# RockChip_RK3588 register map
Vendor: RockChip Electronics Co., Ltd.; Series: RK3588; File version: 0.1
Registers are 32-bit, read-write, no defined reset value unless marked. A register's access mark holds for its fields unless they carry their own. Offsets are from the block's base; [hi:lo] are bit positions; {n}, {i} and the like mark numbered series.

## GRF_PMU1
Base 0xFD58A000
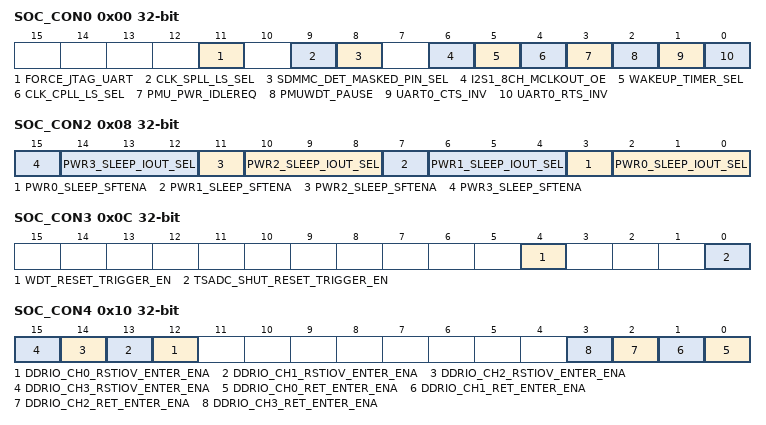
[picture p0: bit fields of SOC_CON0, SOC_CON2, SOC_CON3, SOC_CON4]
0x00 SOC_CON0 — System control register 0
  [11] FORCE_JTAG_UART — Enable GPIO0b5 and GPIO0b6 switch to JTAG function if uart2_rx low last for a specified period of time.
    0=DISABLE; 1=ENABLE
  [9] CLK_SPLL_LS_SEL — Path selection for SPLL clock output.
    0=NORMAL; 1=THROUGH_LEVEL_SHIFT_CELL
  [8] SDMMC_DET_MASKED_PIN_SEL — Polarity selection for sdmmc_det_masked_pin.
    0=LOW_ACTIVE; 1=HIGH_ACTIVE
  [6] I2S1_8CH_MCLKOUT_OE — Output enable for i2s1_8ch_mclkout.
    0=DISABLE; 1=ENABLE
  [5] WAKEUP_TIMER_SEL — Select PMU_TIMER interrupt as PMU wake up source.
    0=INT_0 (PMU_TIMER interrupt 0 selected); 1=INT_1 (PMU_TIMER interrupt 1 selected)
  [4] CLK_CPLL_LS_SEL — Path selection for CPLL clock output.
    0=NORMAL; 1=THROUGH_LEVEL_SHIFT_CELL
  [3] PMU_PWR_IDLEREQ — Enable PD_PMU1 idle request by software.
    0=DISABLE; 1=ENABLE
  [2] PMUWDT_PAUSE — PMU_WDT wdt pause enable. It is used to freeze the watchdog counter during pause mode
    0=DISABLE; 1=ENABLE
  [1] UART0_CTS_INV — Polarity selection for uart0_cts.
    0=LOW_ACTIVE; 1=HIGH_ACTIVE
  [0] UART0_RTS_INV — Polarity selection for uart0_rts.
    0=LOW_ACTIVE; 1=HIGH_ACTIVE
0x04 SOC_CON1 — System control register 1
  [15:0] RESET_WIDTH — The chip output reset width, equals to reset_width*256.
0x08 SOC_CON2 — System control register 2
  [4n+3] PWR{n}_SLEEP_SFTENA (n=0..3) — Enable pwr{n}_sleep by software.
    0=DISABLE; 1=ENABLE
  [4n+2:4n] PWR{n}_SLEEP_IOUT_SEL (n=0..3) — Source selection for pwr{n}_sleep. Default: Controlled by pwr{n}_sleep_sftena
    1=VD_NPU (VD_NPU power off request); 2=VD_GPU (VD_GPU power off request); 3=VD_BIGCORE0 (VD_BIGCORE0 power off request); 4=VD_BIGCORE1 (VD_BIGCORE1 power off request); 5=VD_DSU (VD_DSU power off request); 6=VD_VCODEC (VD_VCODEC power off request); 7=VD_DDR (VD_DDR power off request)
0x0C SOC_CON3 — System control register 3
  [4] WDT_RESET_TRIGGER_EN — Enable WDT reset trigger for DDR fail safe.
    0=DISABLE; 1=ENABLE
  [0] TSADC_SHUT_RESET_TRIGGER_EN — Enable TSADC shut reset trigger for DDR fail safe.
    0=DISABLE; 1=ENABLE
0x10 SOC_CON4 — System control register 4
  [all] fields
    0=DISABLE; 1=ENABLE
  [n+12] DDRIO_CH{n}_RSTIOV_ENTER_ENA (n=0..3) — Enable DDR IO enter retention mode through RSTIOV by hardware for DDR fail safe.
  [n] DDRIO_CH{n}_RET_ENTER_ENA (n=0..3) — Enable DDR IO enter retention mode through RETON/RETOFF or RSTIOV by hardware for DDR fail safe.
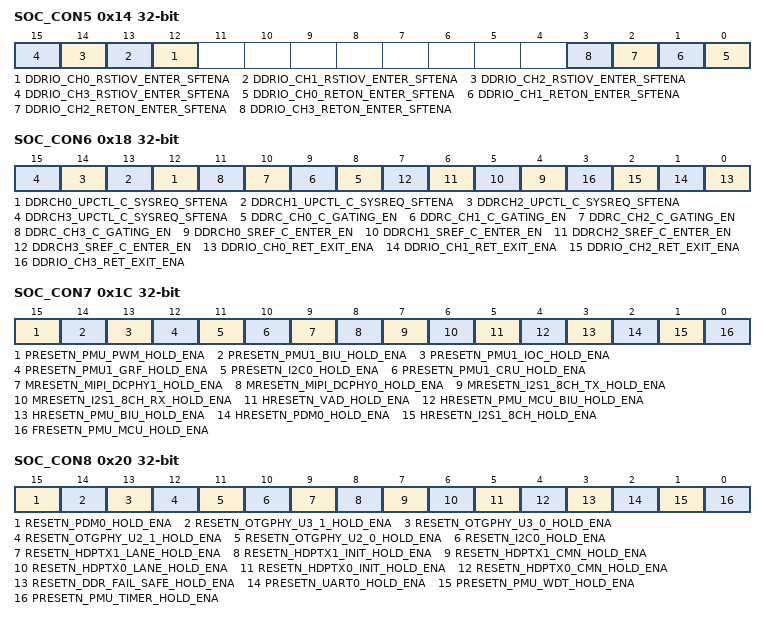
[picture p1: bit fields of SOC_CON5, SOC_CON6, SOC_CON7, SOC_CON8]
0x14 SOC_CON5 — System control register 5
  [all] fields
    0=DISABLE; 1=ENABLE
  [n+12] DDRIO_CH{n}_RSTIOV_ENTER_SFTENA (n=0..3) — Enable DDR IO enter retention mode through RSTIOV by software for DDR fail safe.
  [n] DDRIO_CH{n}_RETON_ENTER_SFTENA (n=0..3) — Enable DDR IO enter retention mode through RETON/RETOFF by software for DDR fail safe.
0x18 SOC_CON6 — System control register 6
  [all] fields
    0=DISABLE; 1=ENABLE
  [n+12] DDRCH{n}_UPCTL_C_SYSREQ_SFTENA (n=0..3) — Enable for DDRC hardware low-power clock request by software.
  [n+8] DDRC_CH{n}_C_GATING_EN (n=0..3) — Enable DDRCTRL's core-clock auto clock gating for DDR fail safe.
  [n+4] DDRCH{n}_SREF_C_ENTER_EN (n=0..3) — Enable DDR self-refresh mode for core-clock domain by hardware for DDR fail safe.
  [n] DDRIO_CH{n}_RET_EXIT_ENA (n=0..3) — Enable DDR IO exit retention mode through RETON/RETOFF or RSTIOV by hardware for DDR fail safe.
0x1C SOC_CON7 — System control register 7
  [all] fields
    0=DISABLE; 1=ENABLE
  [15] PRESETN_PMU_PWM_HOLD_ENA — Enable reset hold for presetn_pmu_pwm.
  [14] PRESETN_PMU1_BIU_HOLD_ENA — Enable reset hold for presetn_pmu1_biu.
  [13] PRESETN_PMU1_IOC_HOLD_ENA — Enable reset hold for presetn_pmu1_ioc.
  [12] PRESETN_PMU1_GRF_HOLD_ENA — Enable reset hold for presetn_pmu1_grf.
  [11] PRESETN_I2C0_HOLD_ENA — Enable reset hold for presetn_i2c0.
  [10] PRESETN_PMU1_CRU_HOLD_ENA — Enable reset hold for presetn_pmu1_cru.
  [9] MRESETN_MIPI_DCPHY1_HOLD_ENA — Enable reset hold for mresetn_mipi_dcphy1.
  [8] MRESETN_MIPI_DCPHY0_HOLD_ENA — Enable reset hold for mresetn_mipi_dcphy0.
  [7] MRESETN_I2S1_8CH_TX_HOLD_ENA — Enable reset hold for mresetn_i2s1_8ch_tx.
  [6] MRESETN_I2S1_8CH_RX_HOLD_ENA — Enable reset hold for mresetn_i2s1_8ch_rx.
  [5] HRESETN_VAD_HOLD_ENA — Enable reset hold for hresetn_vad.
  [4] HRESETN_PMU_MCU_BIU_HOLD_ENA — Enable reset hold for hresetn_pmu_mcu_biu.
  [3] HRESETN_PMU_BIU_HOLD_ENA — Enable reset hold for hresetn_pmu_biu.
  [2] HRESETN_PDM0_HOLD_ENA — Enable reset hold for hresetn_pdm0.
  [1] HRESETN_I2S1_8CH_HOLD_ENA — Enable reset hold for hresetn_i2s1_8ch.
  [0] FRESETN_PMU_MCU_HOLD_ENA — Enable reset hold for fresetn_pmu_mcu.
0x20 SOC_CON8 — System control register 8
  [all] fields
    0=DISABLE; 1=ENABLE
  [15] RESETN_PDM0_HOLD_ENA — Enable reset hold for resetn_pdm0.
  [14] RESETN_OTGPHY_U3_1_HOLD_ENA — Enable reset hold for resetn_otgphy_u3_1.
  [13] RESETN_OTGPHY_U3_0_HOLD_ENA — Enable reset hold for resetn_otgphy_u3_0.
  [12] RESETN_OTGPHY_U2_1_HOLD_ENA — Enable reset hold for resetn_otgphy_u2_1.
  [11] RESETN_OTGPHY_U2_0_HOLD_ENA — Enable reset hold for resetn_otgphy_u2_0.
  [10] RESETN_I2C0_HOLD_ENA — Enable reset hold for resetn_i2c0.
  [9] RESETN_HDPTX1_LANE_HOLD_ENA — Enable reset hold for resetn_hdptx1_lane.
  [8] RESETN_HDPTX1_INIT_HOLD_ENA — Enable reset hold for resetn_hdptx1_init.
  [7] RESETN_HDPTX1_CMN_HOLD_ENA — Enable reset hold for resetn_hdptx1_cmn.
  [6] RESETN_HDPTX0_LANE_HOLD_ENA — Enable reset hold for resetn_hdptx0_lane.
  [5] RESETN_HDPTX0_INIT_HOLD_ENA — Enable reset hold for resetn_hdptx0_init.
  [4] RESETN_HDPTX0_CMN_HOLD_ENA — Enable reset hold for resetn_hdptx0_cmn.
  [3] RESETN_DDR_FAIL_SAFE_HOLD_ENA — Enable reset hold for resetn_ddr_fail_safe.
  [2] PRESETN_UART0_HOLD_ENA — Enable reset hold for presetn_uart0.
  [1] PRESETN_PMU_WDT_HOLD_ENA — Enable reset hold for presetn_pmu_wdt.
  [0] PRESETN_PMU_TIMER_HOLD_ENA — Enable reset hold for presetn_pmu_timer.
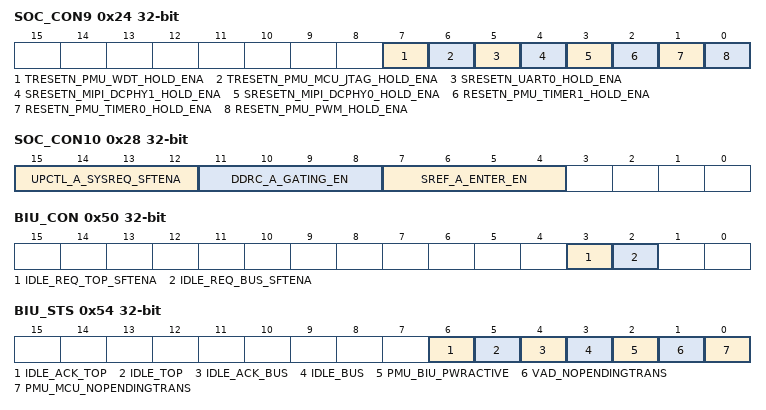
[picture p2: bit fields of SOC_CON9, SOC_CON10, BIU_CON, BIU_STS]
0x24 SOC_CON9 — System control register 9
  [all] fields
    0=DISABLE; 1=ENABLE
  [7] TRESETN_PMU_WDT_HOLD_ENA — Enable reset hold for tresetn_pmu_wdt.
  [6] TRESETN_PMU_MCU_JTAG_HOLD_ENA — Enable reset hold for tresetn_pmu_mcu_jtag.
  [5] SRESETN_UART0_HOLD_ENA — Enable reset hold for sresetn_uart0.
  [4] SRESETN_MIPI_DCPHY1_HOLD_ENA — Enable reset hold for sresetn_mipi_dcphy1.
  [3] SRESETN_MIPI_DCPHY0_HOLD_ENA — Enable reset hold for sresetn_mipi_dcphy0.
  [2] RESETN_PMU_TIMER1_HOLD_ENA — Enable reset hold for resetn_pmu_timer1.
  [1] RESETN_PMU_TIMER0_HOLD_ENA — Enable reset hold for resetn_pmu_timer0.
  [0] RESETN_PMU_PWM_HOLD_ENA — Enable reset hold for resetn_pmu_pwm.
0x28 SOC_CON10 — System control register 10
  [all] fields
    0=DISABLE; 1=ENABLE
  [15:12] UPCTL_A_SYSREQ_SFTENA — Enable for AXI hardware low-power clock request by software.
  [11:8] DDRC_A_GATING_EN — Enable DDRCTRL's AXI-clock auto clock gating for DDR fail safe.
  [7:4] SREF_A_ENTER_EN — Enable DDR self-refresh mode for AXI-clock domain by hardware for DDR fail safe.
0x2C SOC_CON11 — System control register 11
  [31:0] UART2RX_LOW_DLY — uart2_rx low count.
0x50 BIU_CON — BIU interface control register
  [3] IDLE_REQ_TOP_SFTENA — Enable sending idle request to BIU_TOP by software.
    0=DISABLE; 1=ENABLE
  [2] IDLE_REQ_BUS_SFTENA — Enable sending idle request to BIU_BUS by software.
    0=DISABLE; 1=ENABLE
0x54 BIU_STS — BIU interface status register
  [6] IDLE_ACK_TOP ro — BIU_TOP idle acknowledge state.
    0=NAK; 1=ACK
  [5] IDLE_TOP ro — BIU_TOP idle state.
    0=NOT_IDLE; 1=IDLE
  [4] IDLE_ACK_BUS ro — BIU_BUS idle acknowledge state.
    0=NAK; 1=ACK
  [3] IDLE_BUS ro — BIU_BUS idle state.
    0=NOT_IDLE; 1=IDLE
  [2] PMU_BIU_PWRACTIVE ro — Power active status for BIU_PMU.
    0=INACTIVE; 1=ACTIVE
  [1] VAD_NOPENDINGTRANS ro — No pending transfer status for VAD.
    0=INACTIVE; 1=ACTIVE
  [0] PMU_MCU_NOPENDINGTRANS ro — No pending transfer status for PMU_MCU.
    0=INACTIVE; 1=ACTIVE
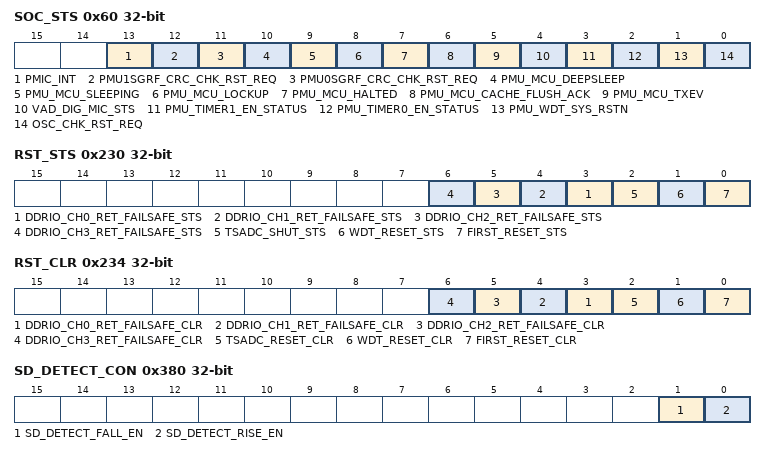
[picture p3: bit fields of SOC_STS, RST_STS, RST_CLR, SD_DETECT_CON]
0x60 SOC_STS — System status register
  [13] PMIC_INT ro — PMIC interrupt status.
    0=INACTIVE; 1=ACTIVE
  [12] PMU1SGRF_CRC_CHK_RST_REQ ro — PMU1SGRF CRC check reset status. It is set to 1 if CRC check error.
    0=INACTIVE; 1=ACTIVE
  [11] PMU0SGRF_CRC_CHK_RST_REQ ro — PMU0SGRF CRC check reset status. It is set to 1 if CRC check error.
    0=INACTIVE; 1=ACTIVE
  [10] PMU_MCU_DEEPSLEEP ro — PMU_MCU deep sleep status.
    0=INACTIVE; 1=ACTIVE
  [9] PMU_MCU_SLEEPING ro — PMU_MCU sleeping status.
    0=INACTIVE; 1=ACTIVE
  [8] PMU_MCU_LOCKUP ro — PMU_MCU lock up status.
    0=INACTIVE; 1=ACTIVE
  [7] PMU_MCU_HALTED ro — PMU_MCU halt status.
    0=INACTIVE; 1=ACTIVE
  [6] PMU_MCU_CACHE_FLUSH_ACK ro — PMU_MCU cache flush acknowledge.
    0=NAK; 1=ACK
  [5] PMU_MCU_TXEV ro — PMU_MCU TXEV status.
    0=INACTIVE; 1=ACTIVE
  [4] VAD_DIG_MIC_STS ro — VAD digital mic status.
    0=INACTIVE; 1=ACTIVE
  [3] PMU_TIMER1_EN_STATUS ro — PMU_TIMER1 enable status.
    0=DISABLE; 1=ENABLE
  [2] PMU_TIMER0_EN_STATUS ro — PMU_TIMER0 enable status.
    0=DISABLE; 1=ENABLE
  [1] PMU_WDT_SYS_RSTN ro — PMU_WDT reset request status.
    0=ACTIVE; 1=INACTIVE
  [0] OSC_CHK_RST_REQ ro — OSC_CHK reset request status.
    0=INACTIVE; 1=ACTIVE
0x80 MEM_CON0 — Memory interface control register 0
  [15:0] PMU1_MEM_CFG_HDSPRA — Interface configuration for HDSPRA type memory in PD_PMU1. Bit[0]: TEST1 Bit[1]: TEST_RNM Bit[4:2]: RM Bit[5]: WMD Bit[7]: LS Bit[11:10]: WPULSE Bit[13:12]: RA Other bits: Reserved
0x84 MEM_CON1 — Memory interface control register 1
  [15:0] MEM_CFG_HDSPRF — Interface configuration for HDSPRF type memory in PD_PMU1. Bit[0]: TEST1 Bit[1]: TEST_RNM Bit[4:2]: RM Bit[5]: WMD Bit[7]: LS Bit[11:10]: WPULSE Bit[13:12]: RA Other bits: Reserved
0x88 MEM_CON2 — Memory interface control register 2
  [15:0] MEM_CFG_HSDPRA_L16 — Lower 16 bits of interface configuration for HSDPRA type memory. Bit[0]: TEST1A Bit[1]: TEST_RNMA Bit[4:2]: RMA Bit[5]: WMDA Bit[7]: LS Bit[11:10]: WPULSE Bit[13:12]: RA Bit[15:14]: WA
0x8C MEM_CON3 — Memory interface control register 3
  [8:0] MEM_CFG_HSDPRA_H9 — Higher 9 bits of interface configuration for HSDPRA type memory. Bit[0]: TEST1B Bit[1]: TEST_RNMB Bit[4:2]: RMB Bit[5]: WMDB Other bits: Reserved
{0x200+4i} OS_REG{i} (i=0..7) — Operation system register {i}
0x230 RST_STS — System reset status register
  [all] fields
    0=INACTIVE; 1=ACTIVE
  [n+3] DDRIO_CH{n}_RET_FAILSAFE_STS ro (n=0..3) — DDRIO channel {n} retention status under DDR fail safe condition.
  [2] TSADC_SHUT_STS ro — TSADC shut status.
  [1] WDT_RESET_STS ro — WDT reset status.
  [0] FIRST_RESET_STS ro — First reset status.
0x234 RST_CLR — System reset status clear register
  [all] fields
    0=DISABLE; 1=ENABLE
  [n+3] DDRIO_CH{n}_RET_FAILSAFE_CLR wo (n=0..3) — Enable clear for DDRIO channel {n} retention status under DDR fail safe condition.
  [2] TSADC_RESET_CLR wo — Enable clear for TSADC shut status.
  [1] WDT_RESET_CLR wo — Enable clear for WDT reset status.
  [0] FIRST_RESET_CLR wo — Enable clear for first reset status.
0x380 SD_DETECT_CON — SDMMC detect control register
  [1] SD_DETECT_FALL_EN — Enable SDMMC detect pin falling edge interrupt.
    0=DISABLE; 1=ENABLE
  [0] SD_DETECT_RISE_EN — Enable SDMMC detect pin rising edge interrupt.
    0=DISABLE; 1=ENABLE
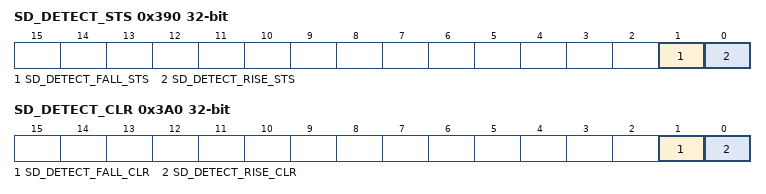
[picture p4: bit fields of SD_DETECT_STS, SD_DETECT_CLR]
0x390 SD_DETECT_STS — SDMMC detect status register
  [1] SD_DETECT_FALL_STS ro — SDMMC detect pin falling edge status.
    0=INACTIVE; 1=ACTIVE
  [0] SD_DETECT_RISE_STS ro — SDMMC detect pin rising edge status.
    0=INACTIVE; 1=ACTIVE
0x3A0 SD_DETECT_CLR — SDMMC detect clear register
  [1] SD_DETECT_FALL_CLR wo — Enable clear for SDMMC detect pin falling edge interrupt.
    0=DISABLE; 1=ENABLE
  [0] SD_DETECT_RISE_CLR wo — Enable clear for SDMMC detect pin rising edge interrupt.
    0=DISABLE; 1=ENABLE
0x3B0 SD_DETECT_CNT — SDMMC detect count register
  [21:0] SD_DET_CNT — SDMMC detect count
